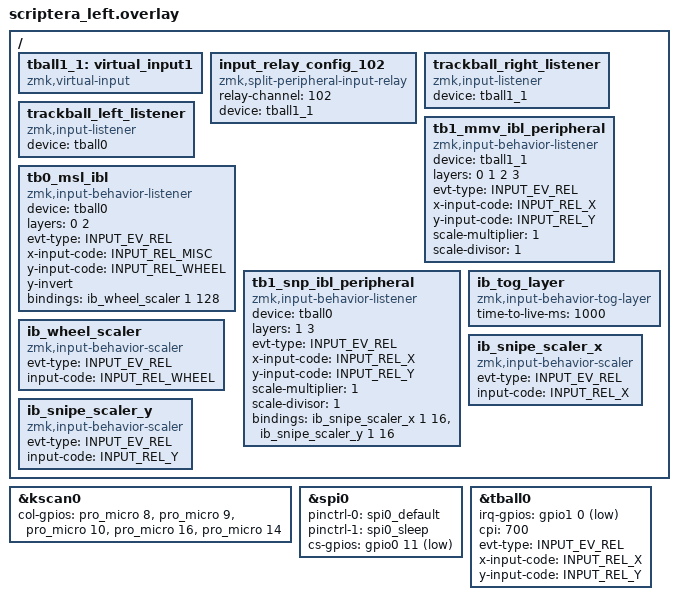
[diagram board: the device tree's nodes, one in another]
#include "scriptera.dtsi"
#include "scriptera_left_tball.dtsi"
#include <zephyr/dt-bindings/input/input-event-codes.h>

&kscan0 {
        col-gpios
            = <&pro_micro 8 (GPIO_ACTIVE_HIGH)> // COL0
            , <&pro_micro 9 (GPIO_ACTIVE_HIGH)> // COL1
            , <&pro_micro 10 (GPIO_ACTIVE_HIGH)> // COL2
            , <&pro_micro 16 (GPIO_ACTIVE_HIGH)> // COL3
            , <&pro_micro 14 (GPIO_ACTIVE_HIGH)> // COL4
        ;
};

&spi0 {
    status = "okay";
    pinctrl-0 = <&spi0_default>;
    pinctrl-1 = <&spi0_sleep>;
    pinctrl-names = "default", "sleep";
    cs-gpios = <&gpio0 11 GPIO_ACTIVE_LOW>;
};

&tball0 {
	    status = "okay";
        irq-gpios = <&gpio1 0 (GPIO_ACTIVE_LOW | GPIO_PULL_UP)>;
        cpi = <700>;
        evt-type = <INPUT_EV_REL>;
        x-input-code = <INPUT_REL_X>;
        y-input-code = <INPUT_REL_Y>;
};

/{
	tball1_1: virtual_input1 {
		compatible = "zmk,virtual-input";
	};
};

/{
	input_relay_config_102 {
		compatible = "zmk,split-peripheral-input-relay";
		relay-channel = <102>;
		device = <&tball1_1>;
	};
};

/{
  trackball_right_listener { 
    compatible = "zmk,input-listener";
    device = <&tball1_1>;
  };

    trackball_left_listener { 
    compatible = "zmk,input-listener";
    device = <&tball0>;
  };
};

/{
    /* input config for mouse move mode on default layer (DEF & MSK) */
    tb1_mmv_ibl_peripheral {
            compatible = "zmk,input-behavior-listener";
            device = <&tball1_1>;
            layers = <0 1 2 3>;
            evt-type = <INPUT_EV_REL>;
            x-input-code = <INPUT_REL_X>;
            y-input-code = <INPUT_REL_Y>;
            scale-multiplier = <1>;
            scale-divisor = <1>;
    };

    /* input config for mouse scroll mode on momentary mouse scoll layer (MSC) */
    tb0_msl_ibl {
            compatible = "zmk,input-behavior-listener";
            device = <&tball0>;
            layers = <0 2>;
            evt-type = <INPUT_EV_REL>;
            x-input-code = <INPUT_REL_MISC>;
            y-input-code = <INPUT_REL_WHEEL>;
            y-invert;
            bindings = <&ib_wheel_scaler 1 128>;
    };

    /* input config for sniper mode on momentary mouse scoll layer (MSC) */
    tb1_snp_ibl_peripheral {
            compatible = "zmk,input-behavior-listener";
            device = <&tball0>;
            layers = <1 3>;
            evt-type = <INPUT_EV_REL>;
            x-input-code = <INPUT_REL_X>;
            y-input-code = <INPUT_REL_Y>;
            scale-multiplier = <1>;
            scale-divisor = <1>;
            bindings = <&ib_snipe_scaler_x 1 16 &ib_snipe_scaler_y 1 16>;
   };

   /* adjust cooldown waiting period for mouse key layer (MSK) after activated */
   ib_tog_layer: ib_tog_layer {
        compatible = "zmk,input-behavior-tog-layer";
        #binding-cells = <1>;
        time-to-live-ms = <1000>;
    };

    /* define a resolution down scaler only for INPUT_REL_WHEEL */
    ib_wheel_scaler: ib_wheel_scaler {
        compatible = "zmk,input-behavior-scaler";
        #binding-cells = <2>;
        evt-type = <INPUT_EV_REL>;
        input-code = <INPUT_REL_WHEEL>;
    };

    ib_snipe_scaler_x: ib_snipe_scaler_x {
        compatible = "zmk,input-behavior-scaler";
        #binding-cells = <2>;
        evt-type = <INPUT_EV_REL>;
        input-code = <INPUT_REL_X>;
    };

    ib_snipe_scaler_y: ib_snipe_scaler_y {
        compatible = "zmk,input-behavior-scaler";
        #binding-cells = <2>;
        evt-type = <INPUT_EV_REL>;
        input-code = <INPUT_REL_Y>;
    };
};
